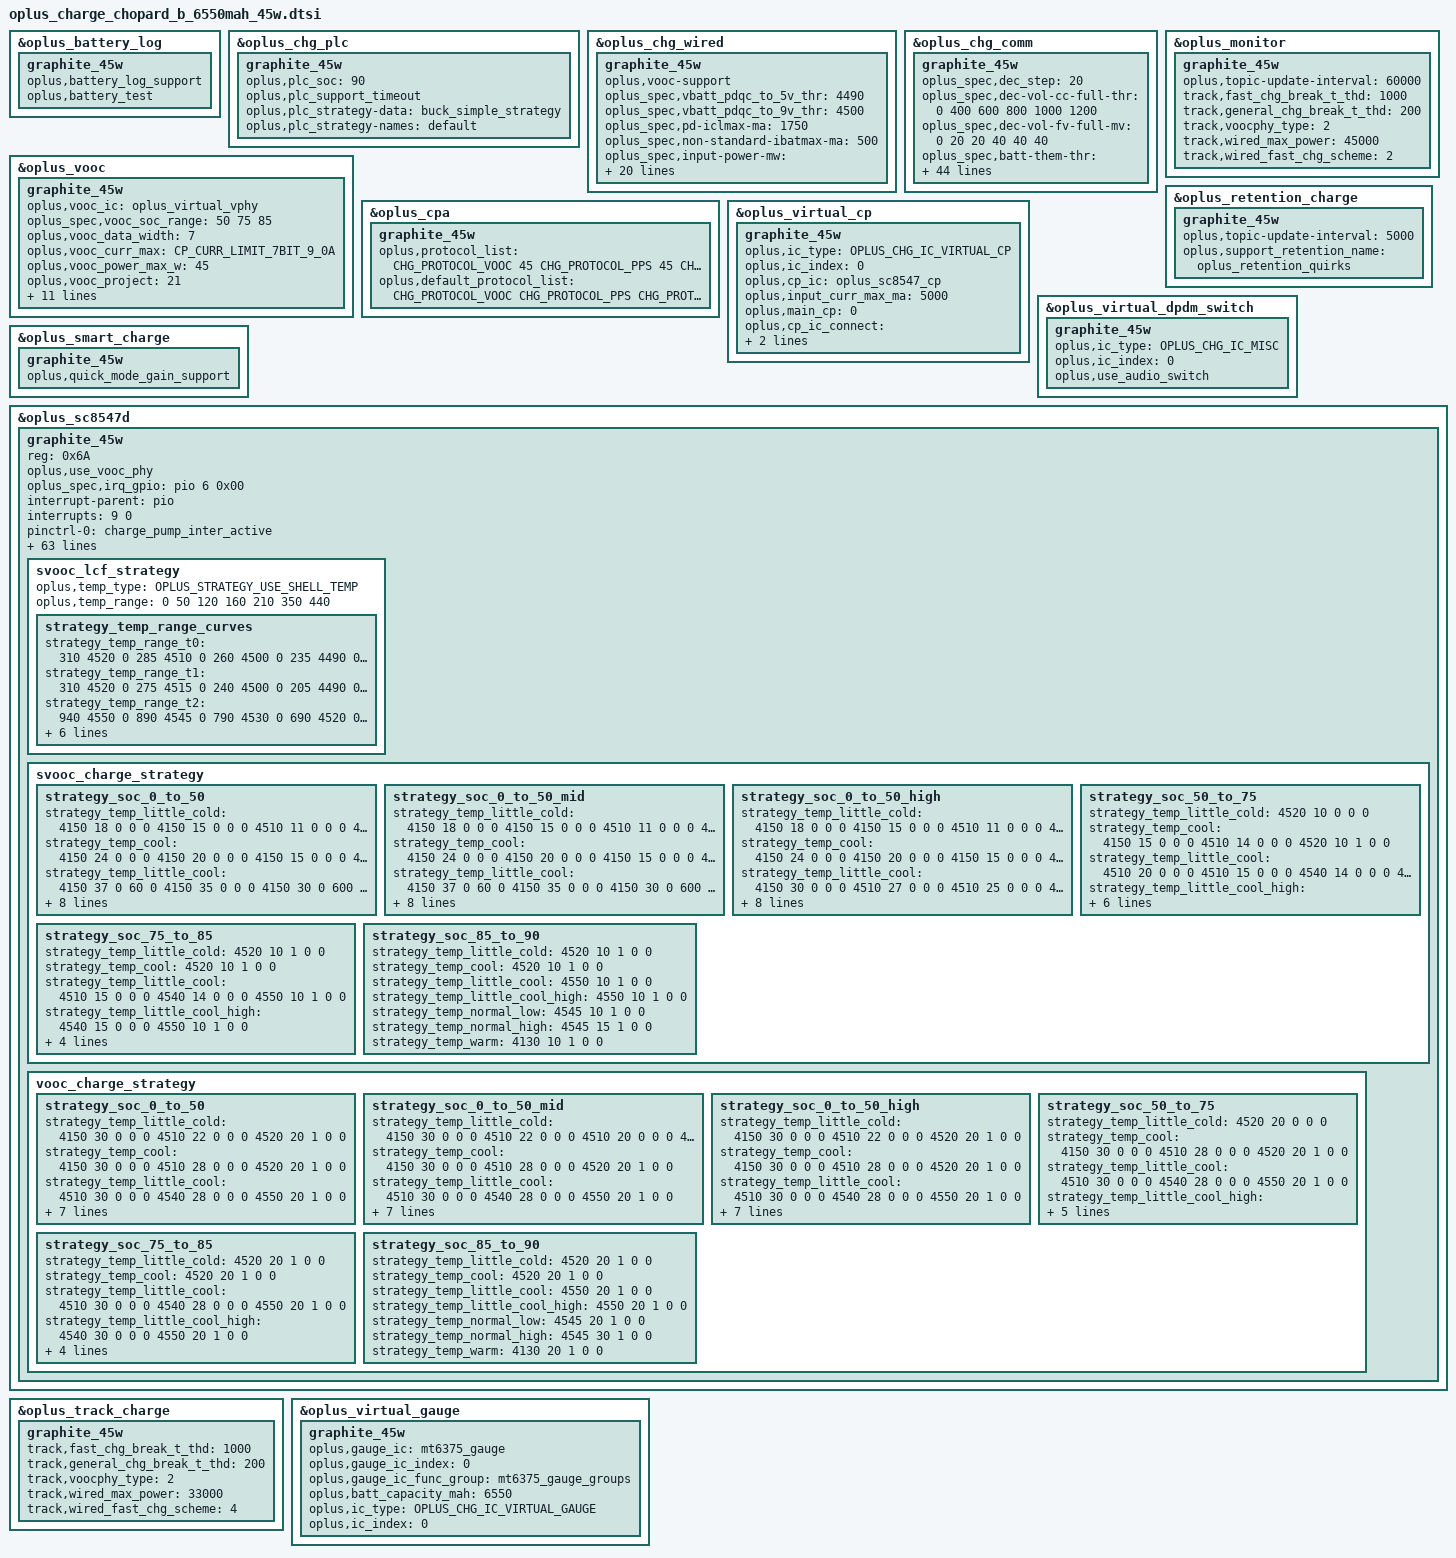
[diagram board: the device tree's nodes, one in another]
// SPDX-License-Identifier: GPL-2.0-only
/*
* Copyright (C) 2021-2020 Oplus. All rights reserved.
*/

/*
 *
 * CPU:MT6835 Barley
 * IRQB
 * CHARGER_PUMP1 (cp irq)               --> GPIO6
 * CC_CNTL_INT_N(cc login irq)          --> GPIO12
 * CHG_INT(main irq)           			--> GPIO3
 * USB_CONTACT_IN_INT           		--> GPIO18
 *
 * GPIO
 * USB_SWITCH_2(uart/ap chagrge)  --> GPIO4
 * VBUS_SHORT(防烧口)           	--> GPIO34
 * CHARGER_PUMP1_SCL               --> GPIO133(CP1_SCL3)
 * CHARGER_PUMP1_SDA               --> GPIO134(CP1_SDA3)
 * CHARGER_buck_SCL & PD_SCL       --> GPIO137(CP1_SCL5)
 * CHARGER_buck_SDA & PD_SDA       --> GPIO138(CP1_SDA5)

 *
 * AP_AUXADC:
 * 0				--> FLASH_LED1_NTC
 * 1				--> NTC_USBCON_TEM (BTB VBUS旁)
 * 2				--> NTC_CHARGE (充电IC旁)
 * 3				--> USB_TEM2_ADC (BB_USB_ADC2)
 * 4				--> USB_TEM1_ADC (BB_USB_ADC1)
 * 5				--> BAT_ID_ADC   (battery id)
 * 6				--> NTC_charging （BTB电池座子旁）
 */


#include <dt-bindings/iio/mt635x-auxadc.h>
#include <dt-bindings/pinctrl/mt6373-pinfunc.h>
#include <dt-bindings/pinctrl/mt65xx.h>
#include "oplus_chg.h"

/* charge start */
&oplus_battery_log {
	graphite_45w {
		oplus,battery_log_support;
		oplus,battery_test;
	};
};

&oplus_chg_plc {
	graphite_45w {
		oplus,plc_soc = <90>;
		oplus,plc_support_timeout;
		oplus,plc_strategy-data = <&buck_simple_strategy>;
		oplus,plc_strategy-names = "default";
	};
};

&oplus_chg_wired {
	graphite_45w {
		oplus,vooc-support;
		oplus_spec,vbatt_pdqc_to_5v_thr = <4490>;
		oplus_spec,vbatt_pdqc_to_9v_thr = <4500>;
		oplus_spec,pd-iclmax-ma = <1750>;
		oplus_spec,non-standard-ibatmax-ma = <500>;
		oplus_spec,input-power-mw = <
			2500		/* OPLUS_WIRED_CHG_MODE_UNKNOWN */
			2500		/* OPLUS_WIRED_CHG_MODE_SDP */
			7500		/* OPLUS_WIRED_CHG_MODE_CDP */
			10000		/* OPLUS_WIRED_CHG_MODE_DCP */
			15000		/* OPLUS_WIRED_CHG_MODE_VOOC */
			18000		/* OPLUS_WIRED_CHG_MODE_QC */
			15750		/* OPLUS_WIRED_CHG_MODE_PD */
		>;
		oplus_spec,led_on-fccmax-ma = <0 1140 4000 4000 4000 4000 4000 1000 0>;
		oplus_spec,fccmax-ma-lv = <
			0 1465  2200 2200 2200 2200 2200 2200 0	/* OPLUS_WIRED_CHG_MODE_UNKNOWN */
			0 2000  2000 2000 2000 2000 2000 2000 0	/* OPLUS_WIRED_CHG_MODE_SDP */
			0 955  1600 1600 1600 1600 1600 1600 0	/* OPLUS_WIRED_CHG_MODE_CDP */
			0 955  2200 2200 2200 2200 2200 2200 0	/* OPLUS_WIRED_CHG_MODE_DCP */
			0 1250  3000 3000 3000 3000 3000 2200 0	/* OPLUS_WIRED_CHG_MODE_VOOC */
			0 1465  4400 4400 4400 4400 4400 3223 0	/* OPLUS_WIRED_CHG_MODE_QC */
			0 955  2800 2800 2800 2800 2800 2800 0	/* OPLUS_WIRED_CHG_MODE_PD */
		>;
		oplus_spec,fccmax-ma-hv = <
			0 1465  2200 2200 2200 2200 2200 2200 0	/* OPLUS_WIRED_CHG_MODE_UNKNOWN */
			0 2000 2000 2000 2000 2000 2000 2000  0	/* OPLUS_WIRED_CHG_MODE_SDP */
			0 955  1600 1600 1600 1600 1600 1600 0	/* OPLUS_WIRED_CHG_MODE_CDP */
			0 955  2200 2200 2200 2200 2200 2200 0	/* OPLUS_WIRED_CHG_MODE_DCP */
			0 1250  3000 3000 3000 3000 3000 2200 0	/* OPLUS_WIRED_CHG_MODE_VOOC */
			0 1465  4400 4400 4400 4400 4400 3223 0	/* OPLUS_WIRED_CHG_MODE_QC */
			0 955  2866 2800 2800 2800 2800 1000 0	/* OPLUS_WIRED_CHG_MODE_PD */
		>;

		oplus_spec,cool_down_pdqc_vol_mv = <9000 9000 9000>;
		oplus_spec,cool_down_pdqc_curr_ma = <1200 1500 2000>;
		oplus_spec,cool_down_vooc_curr_ma = <1200 1500 2000 2500 3000 3000>;
		oplus_spec,cool_down_normal_curr_ma = <1200 1500 2000>;

		oplus_spec,vbus_ov_thr_mv = <11000 11000>;
		oplus_spec,vbus_uv_thr_mv = <3400 3400>;

		/* first data is strategy used temp type */
		oplus,vooc_strategy_name = "cgcl";
		oplus,vooc_strategy_data = <OPLUS_STRATEGY_USE_SHELL_TEMP
					    0   385 3000 1 0
					    385 420 3000 2 0
					    420 440 2000 2 1>;
	};
};

&oplus_chg_comm {
	graphite_45w {
		oplus_spec,dec_step = <20>;
		oplus_spec,dec-vol-cc-full-thr = <0 400 600 800 1000 1200>;
		oplus_spec,dec-vol-fv-full-mv = <0 20 20 40 40 40>;
		oplus_spec,batt-them-thr = <(-100) 0 50 120 160 350 450 530>;
		oplus_spec,iterm-ma = <329>; /* 6370*0.05+10 */
		oplus_spec,removed_bat_decidegc = <390>; /*-39 degree*/
		oplus_spec,fv-mv = <4490 4490 4490 4490 4490 4490 4470 4130 4130>;
		oplus_spec,sw-fv-mv = <4440 4440 4440 4440 4440 4440 4420 4080 4080>;
		oplus_spec,hw-fv-inc-mv = <0 18 18 18 18 18 18 18 0>;
		oplus_spec,sw-over-fv-mv = <4500 4500 4500 4500 4500 4500 4480 4140 4140>;
		oplus_spec,sw-over-fv-dec-mv = <8>;
		oplus_spec,non-standard-sw-fv-mv = <3930>;
		oplus_spec,non-standard-fv-mv = <3980>;
		oplus_spec,non-standard-hw-fv-inc-mv = <18>;
		oplus_spec,non-standard-sw-over-fv-mv = <3990>;
		oplus_spec,non-standard-vbatdet-mv = <3680>;
		oplus_spec,wired-vbatdet-mv = <0 4190 4290 4390 4390 4390 4370 4030 0>;
		oplus_spec,fcc-gear-thr-mv = <4180>;
		oplus_spec,vbatt-ov-thr-mv = <4600>;

		oplus_spec,full_pre_ffc_judge;
		oplus_spec,full-pre-ffc-mv = <4485>;
		oplus_spec,ffc-temp-thr = <120 210 350 440>;
		oplus_spec,wired-ffc-step-max = <2>;
		oplus_spec,wired-ffc-fv-mv = <4630 4630>;

		oplus_spec,wired-ffc-fv-cutoff-mv = <4545 4545 4500 4545 4545 4490>;
		oplus_spec,wired-ffc-fcc-ma = <2000 2000 1500 1900 1900 1000>;
		oplus_spec,wired-ffc-fcc-cutoff-ma = <1800 1800 1300 1700 1700 900>;
		oplus_spec,vbat_uv_thr_mv = <3300>;
		oplus_spec,vbat_charging_uv_thr_mv = <3200>;

		/*If use subboard NTC as battery temp, config it as 20, otherwise 0 */
		oplus_spec,tbatt_power_off_cali_temp = <0>;
		oplus_spec,poweroff_high_batt_temp = <720>;
		oplus_spec,poweroff_emergency_batt_temp = <770>;
		oplus,vooc_show_ui_soc_decimal;
		oplus,ui_soc_decimal_speedmin = <20>;
		oplus,gauge_stuck_jump_support;
		oplus,gauge_stuck_threshold = <15>;
		oplus,gauge_stuck_time = <50>;
		oplus,smooth_switch;
		oplus,reserve_chg_soc = <2>;
	};
};

&oplus_monitor {
	graphite_45w {
		oplus,topic-update-interval = <60000>;

		track,fast_chg_break_t_thd = <1000>;
		track,general_chg_break_t_thd = <200>;
		track,voocphy_type = <2>;
		track,wired_max_power = <45000>;
		track,wired_fast_chg_scheme = <2>;
	};
};

&oplus_vooc {
	graphite_45w {
		oplus,vooc_ic = <&oplus_virtual_vphy>;

		oplus_spec,vooc_soc_range = <50 75 85>;

		oplus,vooc_data_width = <7>;
		oplus,vooc_curr_max = <CP_CURR_LIMIT_7BIT_9_0A>; /* 45W: 11V 8.2A(IBUS *2) */
		oplus,vooc_power_max_w = <45>;
		oplus,vooc_project = <21>;
		oplus,vooc_curr_table_type = <VOOC_CP_CURR_TABLE>;
		oplus,voocphy_support = <2>; /* AP_SINGLE_CP_VOOCPHY */
		oplus,support_fake_vooc_check;
		oplus,subboard_ntc_abnormal_current = <4000>;

		oplus,abnormal_over_80w_adapter_current = <CP_CURR_LIMIT_7BIT_15_0A CP_CURR_LIMIT_7BIT_15_0A
						CP_CURR_LIMIT_7BIT_14_0A CP_CURR_LIMIT_7BIT_14_0A
						CP_CURR_LIMIT_7BIT_12_0A CP_CURR_LIMIT_7BIT_12_0A
						CP_CURR_LIMIT_7BIT_10_0A CP_CURR_LIMIT_7BIT_10_0A
						CP_CURR_LIMIT_7BIT_8_0A CP_CURR_LIMIT_7BIT_8_0A
						CP_CURR_LIMIT_7BIT_6_0A CP_CURR_LIMIT_7BIT_6_0A
						CP_CURR_LIMIT_7BIT_4_0A CP_CURR_LIMIT_7BIT_4_0A>;

		oplus,abnormal_adapter_current = <CURR_LIMIT_7BIT_7_5A CURR_LIMIT_7BIT_7_5A
						CP_CURR_LIMIT_7BIT_5_0A CP_CURR_LIMIT_7BIT_5_0A
						CP_CURR_LIMIT_7BIT_4_0A CP_CURR_LIMIT_7BIT_4_0A
						CP_CURR_LIMIT_7BIT_3_0A CP_CURR_LIMIT_7BIT_3_0A
						CP_CURR_LIMIT_7BIT_2_0A CP_CURR_LIMIT_7BIT_2_0A>;

		/* first data is strategy used temp type */
		oplus,general_strategy_name = "cgcl";
		oplus,general_strategy_data = < OPLUS_STRATEGY_USE_SHELL_TEMP
						0   385 CP_CURR_LIMIT_7BIT_9_0A 1 0
						0   395 CP_CURR_LIMIT_7BIT_8_0A 2 0
						385 420 CP_CURR_LIMIT_7BIT_6_0A 3 1
						395 440 CP_CURR_LIMIT_7BIT_4_0A 4 2
						420 440 CP_CURR_LIMIT_7BIT_4_0A 4 3>;
	};
};

&oplus_retention_charge {
	graphite_45w {
		oplus,topic-update-interval = <5000>;
		oplus,support_retention_name = "oplus_retention_quirks";
	};
};

&oplus_cpa {
	graphite_45w {
		oplus,protocol_list = <CHG_PROTOCOL_VOOC 45
							CHG_PROTOCOL_PPS 45
							CHG_PROTOCOL_PD 15>;
		oplus,default_protocol_list = <CHG_PROTOCOL_VOOC
							CHG_PROTOCOL_PPS
							CHG_PROTOCOL_PD>;
	};
};

&oplus_virtual_cp {
	graphite_45w {
		oplus,ic_type = <OPLUS_CHG_IC_VIRTUAL_CP>;
		oplus,ic_index = <0>;

		oplus,cp_ic = <&oplus_sc8547_cp>;
		oplus,input_curr_max_ma = <5000>;
		oplus,main_cp = <0>;
		oplus,cp_ic_connect = <OPLUS_CHG_IC_CONNECT_PARALLEL>;

		oplus,reg_proc_node;
	};
};

&oplus_virtual_dpdm_switch {
	graphite_45w {
		oplus,ic_type = <OPLUS_CHG_IC_MISC>;
		oplus,ic_index = <0>;

		oplus,use_audio_switch;
	};
};

&oplus_smart_charge {
	graphite_45w {
		oplus,quick_mode_gain_support;
	};
};

&oplus_sc8547d {
	graphite_45w {
		reg = <0x6A>;

		oplus,use_vooc_phy;
		oplus_spec,irq_gpio = <&pio 6 0x00>;
		interrupt-parent = <&pio>;
		interrupts = <9 0>;

		pinctrl-names = "charging_inter_active", "charging_inter_sleep";
		pinctrl-0 = <&charge_pump_inter_active>;
		pinctrl-1 = <&charge_pump_inter_sleep>;

		oplus,ic_type = <OPLUS_CHG_IC_VPHY>;
		oplus,ic_index = <0>;
		oplus,vooc-version = <VOOC_VERSION_5_0>;

		ocp_reg = <0xd>;
		ovp_reg = <0x36>;/* vbat ovp 4.85v */
		vbus_ovp_reg = /bits/ 8 <0x5A>;
		oplus_spec,slave_cp_enable_thr = <1400>;		//2000-100mA
		oplus_spec,slave_cp_disable_thr_high = <1100>;	//1500+100mA
		oplus_spec,voocphy_current_default = <73>;

		oplus_spec,svooc_cool_down_current_limit = <82 20 20 24 30 34 40 44 50 54 60 64 70 74>;
		oplus_spec,vooc_cool_down_current_limit = <30 20 20 24 30 34 40 44 50 54 60 64 70 74>;

		oplus_spec,vooc_bad_volt = <3800 3800 3800 3800>;
		oplus_spec,vooc_bad_volt_suspend = <3800 3800 3800 3800>;
		oplus_spec,vooc_bad_volt_check_head_mask = /bits/ 8 <0x3>; /* VOOC 2.0/VOOC3.0 */
		oplus_spec,ap_control_allow;

		oplus_spec,vooc_low_temp = <0>;
		oplus_spec,vooc_little_cold_temp = <50>;
		oplus_spec,vooc_cool_temp = <120>;
		oplus_spec,vooc_little_cool_temp = <160>;
		oplus_spec,vooc_little_cool_high_temp = <210>;
		oplus_spec,vooc_normal_low_temp = <350>;
		oplus_spec,vooc_normal_high_temp = <440>;
		oplus_spec,vooc_high_temp = <530>;
		oplus_spec,vooc_over_high_temp = <530>;
		oplus_spec,vooc_strategy_normal_current = <122>;
		oplus_spec,vooc_normal_to_little_cool_current = <100>;
		oplus_spec,vooc_multistep_initial_batt_temp = <1000>;
		oplus_spec,fastchg_timeout_time_init = <171000>;

		oplus_spec,vooc_low_soc = <0>;
		oplus_spec,vooc_high_soc = <90>;
		oplus_spec,vooc_warm_vol_thr = <4000>;
		oplus_spec,vooc_warm_soc_thr = <55>;

		oplus_spec,voocphy_freq_mincore = <1800000>;
		oplus_spec,voocphy_freq_midcore = <1800000>;
		oplus_spec,voocphy_freq_maxcore = <1800000>;
		oplus_spec,voocphy_current_change_timeout = <100>;
		oplus_spec,copycat_vooc_support;
		oplus_spec,copycat_vooc_accuracy_value = <105>;
		oplus,copycat-vooc-count = <4>;

		oplus_spec,voocphy_ibat_over_current = <9600>;
		oplus_spec,voocphy_svooc_cp_max_ibus = <4500>;
		oplus_spec,voocphy_vooc_cp_max_ibus = <4500>;
		oplus_spec,voocphy_cp_max_ibus = <4500>;

		oplus,workaround_for_100w;
		oplus_spec,vooc_little_cold_full_voltage = <4520>;
		oplus_spec,vooc_cool_full_voltage = <4520>;
		oplus_spec,vooc_little_cool_full_voltage = <4550>;
		oplus_spec,vooc_little_cool_high_full_voltage = <4550>;
		oplus_spec,vooc_warm_full_voltage = <4130>;
		oplus_spec,vooc_1time_full_voltage = <4555>;
		oplus_spec,vooc_ntime_full_voltage = <4545>;
		oplus_spec,soc_range = <0 20 35 55 75 85 90>;

		svooc_batt_sys_curve = <0 1 0 1 0 0 0	// 4000mA
					1 1 1 1 0 0 0	// 4604mV
					0 0 1 1 0 1 0	// 2600mA
					1 1 1 1 0 0 0	// 4604mV
					0 0 0 1 0 1 1	// 1100mA
					1 1 1 1 0 0 0>;	// 4604mV

		vooc_batt_sys_curve =  <0 1 0 1 0 0 0	// 4000mA
					1 1 1 1 0 0 0	// 4604mV
					0 0 1 1 0 1 0	// 2600mA
					1 1 1 1 0 0 0	// 4604mV
					0 0 0 1 0 1 1	// 1100mA
					1 1 1 1 0 0 0>;	// 4604mV
		svooc_lcf_strategy {
			oplus,temp_type = <OPLUS_STRATEGY_USE_SHELL_TEMP>;
			oplus,temp_range = <0 50 120 160 210 350 440>;

			strategy_temp_range_curves {
				strategy_temp_range_t0 = <310 4520 0
								 285 4510 0
								 260 4500 0
								 235 4490 0
								 210 4480 1>;
				strategy_temp_range_t1 = <310 4520 0
								 275 4515 0
								 240 4500 0
								 205 4490 0
								 170 4480 1>;
				strategy_temp_range_t2 = <940 4550 0
								 890 4545 0
								 790 4530 0
								 690 4520 0
								 540 4510 1>;
				strategy_temp_range_t3 = <1940 4550 0
								 1890 4545 0
								 1790 4530 0
								 1690 4520 0
								 1540 4510 1>;
				strategy_temp_range_t4 = <1940 4531 0
								 1890 4526 0
								 1790 4516 0
								 1690 4506 0
								 1540 4496 1>;
				strategy_temp_range_t5 = <2250 4527 0
								 2050 4511 0
								 1700 4504 0
								 1350 4495 0
								 1000 4485 1>;
			};
		};

		svooc_charge_strategy {
			strategy_soc_0_to_50 { /* 0 ~ 20 */
				strategy_temp_little_cold =	<4150 18 0 0 0
								 4150 15 0 0 0
								 4510 11 0 0 0
								 4520 10 1 0 0>;
				strategy_temp_cool = <4150 24 0 0 0
								 4150 20 0 0 0
								 4150 15 0 0 0
								 4510 14 0 0 0
								 4520 10 1 0 0>;
				strategy_temp_little_cool =	<4150 37 0 60 0
								 4150 35 0 0 0
								 4150 30 0 600 0
								 4510 27 0 0 0
								 4510 25 0 600 0
								 4510 20 0 0 0
								 4510 15 0 0 0
								 4540 14 0 0 0
								 4550 10 1 0 0>;
				strategy_temp_little_cool_high = <4200 41 0 60 0
								 4200 40 0 0 0
								 4230 37 0 0 0
								 4230 35 0 0 0
								 4510 31 0 0 0
								 4510 30 0 600 0
								 4510 25 0 600 0
								 4510 20 0 0 0
								 4540 18 0 0 0
								 4540 15 0 0 0
								 4550 10 1 0 0>;
				strategy_temp_normal_low =	<4200 41 0 60 0
								 4200 40 0 0 0
								 4230 37 0 0 0
								 4230 35 0 0 0
								 4510 31 0 0 0
								 4510 30 0 600 0
								 4510 25 0 600 0
								 4510 20 0 0 0
								 4540 18 0 0 0
								 4540 15 0 0 0
								 4545 10 1 0 0>;
				strategy_temp_normal_high =	<4200 41 0 60 0
								 4200 40 0 0 0
								 4230 37 0 0 0
								 4230 35 0 0 0
								 4510 31 0 0 0
								 4510 30 0 600 0
								 4510 25 0 600 0
								 4510 20 0 0 0
								 4540 18 0 0 0
								 4545 15 1 0 0>;
				strategy_temp_warm = <4120 17 0 0 0
								 4120 15 0 0 0
								 4130 10 1 0 0>;
			};

			strategy_soc_0_to_50_mid { /* 21 ~ 35 */
				strategy_temp_little_cold =	<4150 18 0 0 0
								 4150 15 0 0 0
								 4510 11 0 0 0
								 4520 10 1 0 0>;
				strategy_temp_cool = <4150 24 0 0 0
								 4150 20 0 0 0
								 4150 15 0 0 0
								 4510 14 0 0 0
								 4520 10 1 0 0>;
				strategy_temp_little_cool =	<4150 37 0 60 0
								 4150 35 0 0 0
								 4150 30 0 600 0
								 4510 27 0 0 0
								 4510 25 0 600 0
								 4510 20 0 0 0
								 4510 15 0 0 0
								 4540 14 0 0 0
								 4550 10 1 0 0>;
				strategy_temp_little_cool_high = <4200 41 0 60 0
								 4200 40 0 0 0
								 4230 37 0 0 0
								 4230 35 0 0 0
								 4510 31 0 0 0
								 4510 30 0 600 0
								 4510 25 0 600 0
								 4510 20 0 0 0
								 4540 18 0 0 0
								 4540 15 0 0 0
								 4550 10 1 0 0>;
				strategy_temp_normal_low = <4200 41 0 60 0
								 4200 40 0 0 0
								 4230 37 0 0 0
								 4230 35 0 0 0
								 4510 31 0 0 0
								 4510 30 0 600 0
								 4510 25 0 600 0
								 4510 20 0 0 0
								 4540 18 0 0 0
								 4540 15 0 0 0
								 4545 10 1 0 0>;
				strategy_temp_normal_high =	<4200 41 0 60 0
								 4200 40 0 0 0
								 4230 37 0 0 0
								 4230 35 0 0 0
								 4510 31 0 0 0
								 4510 30 0 600 0
								 4510 25 0 600 0
								 4510 20 0 0 0
								 4540 18 0 0 0
								 4545 15 1 0 0>;
				strategy_temp_warm = <4120 17 0 0 0
								 4120 15 0 0 0
								 4130 10 1 0 0>;
			};

			strategy_soc_0_to_50_high { /* 36 ~ 55 */
				strategy_temp_little_cold =	<4150 18 0 0 0
								 4150 15 0 0 0
								 4510 11 0 0 0
								 4520 10 1 0 0>;
				strategy_temp_cool = <4150 24 0 0 0
								 4150 20 0 0 0
								 4150 15 0 0 0
								 4510 14 0 0 0
								 4520 10 1 0 0>;
				strategy_temp_little_cool =	<4150 30 0 0 0
								 4510 27 0 0 0
								 4510 25 0 0 0
								 4510 20 0 0 0
								 4510 15 0 0 0
								 4540 14 0 0 0
								 4550 10 1 0 0>;
				strategy_temp_little_cool_high = <4510 30 0 0 0
								 4510 25 0 0 0
								 4510 20 0 0 0
								 4540 18 0 0 0
								 4540 15 0 0 0
								 4550 10 1 0 0>;
				strategy_temp_normal_low =	<4200 41 0 60 0
								 4200 40 0 0 0
								 4230 37 0 0 0
								 4230 35 0 0 0
								 4510 31 0 0 0
								 4510 30 0 600 0
								 4510 25 0 600 0
								 4510 20 0 0 0
								 4540 18 0 0 0
								 4540 15 0 0 0
								 4545 10 1 0 0>;
				strategy_temp_normal_high =	<4200 41 0 60 0
								 4200 40 0 0 0
								 4230 37 0 0 0
								 4230 35 0 0 0
								 4510 31 0 0 0
								 4510 30 0 600 0
								 4510 25 0 600 0
								 4510 20 0 0 0
								 4540 18 0 0 0
								 4545 15 1 0 0>;
				strategy_temp_warm = <4120 17 0 0 0
								 4120 15 0 0 0
								 4130 10 1 0 0>;
			};

			strategy_soc_50_to_75 { /* 56 ~ 75 */
				strategy_temp_little_cold =	<4520 10 0 0 0>;
				strategy_temp_cool = <4150 15 0 0 0
								 4510 14 0 0 0
								 4520 10 1 0 0>;
				strategy_temp_little_cool =	<4510 20 0 0 0
								 4510 15 0 0 0
								 4540 14 0 0 0
								 4550 10 1 0 0>;
				strategy_temp_little_cool_high = <4510 20 0 0 0
								 4540 18 0 0 0
								 4540 15 0 0 0
								 4550 10 1 0 0>;
				strategy_temp_normal_low = <4510 25 0 0 0
								 4510 20 0 0 0
								 4540 18 0 0 0
								 4540 15 0 0 0
								 4545 10 1 0 0>;
				strategy_temp_normal_high =	<4510 25 0 0 0
								 4510 20 0 0 0
								 4540 18 0 0 0
								 4545 15 1 0 0>;
				strategy_temp_warm = <4130 10 1 0 0>;
			};

			strategy_soc_75_to_85 {	/*76 ~ 85*/
				strategy_temp_little_cold =	<4520 10 1 0 0>;
				strategy_temp_cool = <4520 10 1 0 0>;
				strategy_temp_little_cool =	<4510 15 0 0 0
								 4540 14 0 0 0
								 4550 10 1 0 0>;
				strategy_temp_little_cool_high = <4540 15 0 0 0
								 4550 10 1 0 0>;
				strategy_temp_normal_low =	<4540 15 0 0 0
								 4545 10 1 0 0>;
				strategy_temp_normal_high =	<4545 15 1 0 0>;
				strategy_temp_warm = <4130 10 1 0 0>;
			};

			strategy_soc_85_to_90 { /*86 ~ 95*/
				strategy_temp_little_cold =	<4520 10 1 0 0>;
				strategy_temp_cool = <4520 10 1 0 0>;
				strategy_temp_little_cool =	<4550 10 1 0 0>;
				strategy_temp_little_cool_high = <4550 10 1 0 0>;
				strategy_temp_normal_low =	<4545 10 1 0 0>;
				strategy_temp_normal_high =	<4545 15 1 0 0>;
				strategy_temp_warm = <4130 10 1 0 0>;
			};
		};

		vooc_charge_strategy {
			strategy_soc_0_to_50 {
				strategy_temp_little_cold =	<4150 30 0 0 0
								 4510 22 0 0 0
								 4520 20 1 0 0>;
				strategy_temp_cool = <4150 30 0 0 0
								 4510 28 0 0 0
								 4520 20 1 0 0>;
				strategy_temp_little_cool =	<4510 30 0 0 0
								 4540 28 0 0 0
								 4550 20 1 0 0>;
				strategy_temp_little_cool_high = <4540 30 0 0 0
								 4550 20 1 0 0>;
				strategy_temp_normal_low =	<4540 30 0 0 0
								 4545 20 1 0 0>;
				strategy_temp_normal_high =	<4545 30 1 0 0>;
				strategy_temp_warm = <4120 30 0 0 0
								 4130 20 1 0 0>;
			};

			strategy_soc_0_to_50_mid {
				strategy_temp_little_cold =	<4150 30 0 0 0
								 4510 22 0 0 0
								 4510 20 0 0 0
								 4520 18 1 0 0>;
				strategy_temp_cool = <4150 30 0 0 0
								 4510 28 0 0 0
								 4520 20 1 0 0>;
				strategy_temp_little_cool =	<4510 30 0 0 0
								 4540 28 0 0 0
								 4550 20 1 0 0>;
				strategy_temp_little_cool_high = <4540 30 0 0 0
								 4550 20 1 0 0>;
				strategy_temp_normal_low = <4540 30 0 0 0
								 4545 20 1 0 0>;
				strategy_temp_normal_high =	<4545 30 1 0 0>;
				strategy_temp_warm = <4120 30 0 0 0
								 4130 20 1 0 0>;
			};

			strategy_soc_0_to_50_high {
				strategy_temp_little_cold =	<4150 30 0 0 0
								 4510 22 0 0 0
								 4520 20 1 0 0>;
				strategy_temp_cool = <4150 30 0 0 0
								 4510 28 0 0 0
								 4520 20 1 0 0>;
				strategy_temp_little_cool =	<4510 30 0 0 0
								 4540 28 0 0 0
								 4550 20 1 0 0>;
				strategy_temp_little_cool_high = <4540 30 0 0 0
								 4550 20 1 0 0>;
				strategy_temp_normal_low =	<4540 30 0 0 0
								 4545 20 1 0 0>;
				strategy_temp_normal_high =	<4545 30 1 0 0>;
				strategy_temp_warm = <4120 30 0 0 0
								 4130 20 1 0 0>;
			};

			strategy_soc_50_to_75 {
				strategy_temp_little_cold =	<4520 20 0 0 0>;
				strategy_temp_cool = <4150 30 0 0 0
								 4510 28 0 0 0
								 4520 20 1 0 0>;
				strategy_temp_little_cool =	<4510 30 0 0 0
								 4540 28 0 0 0
								 4550 20 1 0 0>;
				strategy_temp_little_cool_high = <4540 30 0 0 0
								 4550 20 1 0 0>;
				strategy_temp_normal_low = <4540 30 0 0 0
								 4545 20 1 0 0>;
				strategy_temp_normal_high =	<4545 30 1 0 0>;
				strategy_temp_warm = <4130 20 1 0 0>;
			};

			strategy_soc_75_to_85 {
				strategy_temp_little_cold =	<4520 20 1 0 0>;
				strategy_temp_cool = <4520 20 1 0 0>;
				strategy_temp_little_cool =	<4510 30 0 0 0
								 4540 28 0 0 0
								 4550 20 1 0 0>;
				strategy_temp_little_cool_high = <4540 30 0 0 0
								 4550 20 1 0 0>;
				strategy_temp_normal_low = <4540 30 0 0 0
								 4545 20 1 0 0>;
				strategy_temp_normal_high =	<4545 30 1 0 0>;
				strategy_temp_warm = <4130 20 1 0 0>;
			};

			strategy_soc_85_to_90 {
				strategy_temp_little_cold =	<4520 20 1 0 0>;
				strategy_temp_cool = <4520 20 1 0 0>;
				strategy_temp_little_cool =	<4550 20 1 0 0>;
				strategy_temp_little_cool_high = <4550 20 1 0 0>;
				strategy_temp_normal_low =	<4545 20 1 0 0>;
				strategy_temp_normal_high =	<4545 30 1 0 0>;
				strategy_temp_warm = <4130 20 1 0 0>;
			};
		};
	};
};

&oplus_track_charge {
	graphite_45w {
		track,fast_chg_break_t_thd = <1000>;
		track,general_chg_break_t_thd = <200>;
		track,voocphy_type = <2>;
		track,wired_max_power = <33000>;
		track,wired_fast_chg_scheme = <4>;
	};
};

/* chagrge end */
&oplus_virtual_gauge {
	graphite_45w {
		oplus,gauge_ic = <&mt6375_gauge>;
		oplus,gauge_ic_index = <0>;
		oplus,gauge_ic_func_group = <&mt6375_gauge_groups>;
		oplus,batt_capacity_mah = <6550>;
		oplus,ic_type = <OPLUS_CHG_IC_VIRTUAL_GAUGE>;
		oplus,ic_index = <0>;
	};
};
